# iospear320 register map
Registers from a debugger description file.
Registers are 32-bit, access not given, no defined reset value unless marked. A register's access mark holds for its fields unless they carry their own. Addresses are absolute; registers are grouped by the start of their names; lines under a group give offsets from that group; [hi:lo] are bit positions; {n}, {i} and the like mark numbered series; 'fields as' and 'values as' point back to an identical list; <NAME> marks a mode.

## PLL1
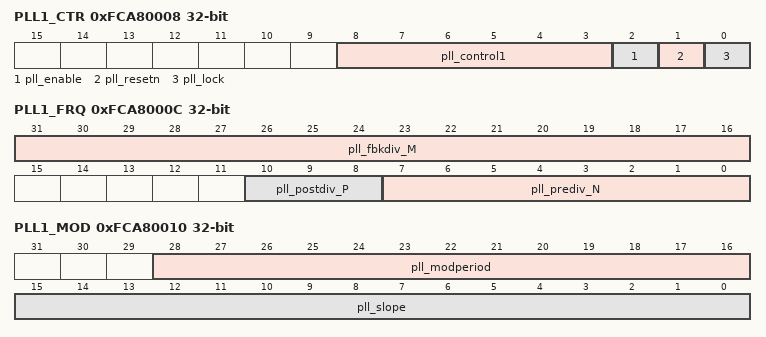
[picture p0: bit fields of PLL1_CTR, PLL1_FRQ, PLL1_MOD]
0xFCA80008 PLL1_CTR
  [8:3] pll_control1, [2] pll_enable, [1] pll_resetn, [0] pll_lock
0xFCA8000C PLL1_FRQ
  [31:16] pll_fbkdiv_M, [10:8] pll_postdiv_P, [7:0] pll_prediv_N
0xFCA80010 PLL1_MOD
  [28:16] pll_modperiod, [15:0] pll_slope

## PLL2
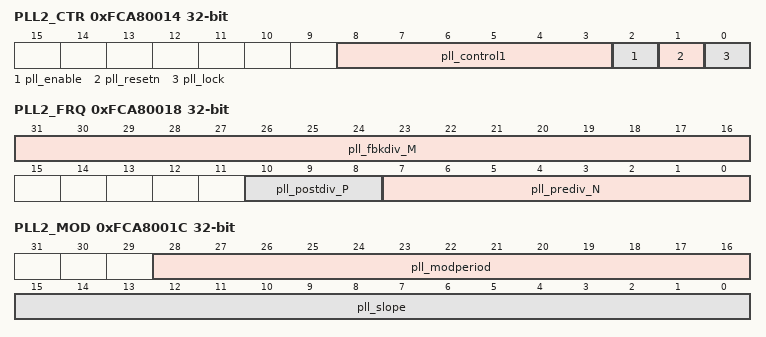
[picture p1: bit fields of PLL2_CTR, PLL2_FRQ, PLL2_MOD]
0xFCA80014 PLL2_CTR
  [8:3] pll_control1, [2] pll_enable, [1] pll_resetn, [0] pll_lock
0xFCA80018 PLL2_FRQ
  [31:16] pll_fbkdiv_M, [10:8] pll_postdiv_P, [7:0] pll_prediv_N
0xFCA8001C PLL2_MOD
  [28:16] pll_modperiod, [15:0] pll_slope

## PERIP1
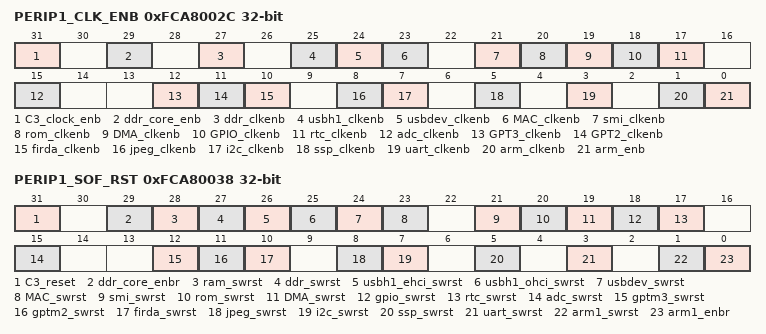
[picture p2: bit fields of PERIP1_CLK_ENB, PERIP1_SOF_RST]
0xFCA8002C PERIP1_CLK_ENB
  [31] C3_clock_enb, [29] ddr_core_enb, [27] ddr_clkenb, [25] usbh1_clkenb, [24] usbdev_clkenb, [23] MAC_clkenb, [21] smi_clkenb, [20] rom_clkenb, [19] DMA_clkenb, [18] GPIO_clkenb, [17] rtc_clkenb, [15] adc_clkenb, [12] GPT3_clkenb, [11] GPT2_clkenb, [10] firda_clkenb, [8] jpeg_clkenb, [7] i2c_clkenb, [5] ssp_clkenb, [3] uart_clkenb, [1] arm_clkenb, [0] arm_enb
0xFCA80038 PERIP1_SOF_RST
  [31] C3_reset, [29] ddr_core_enbr, [28] ram_swrst, [27] ddr_swrst, [26] usbh1_ehci_swrst, [25] usbh1_ohci_swrst, [24] usbdev_swrst, [23] MAC_swrst, [21] smi_swrst, [20] rom_swrst, [19] DMA_swrst, [18] gpio_swrst, [17] rtc_swrst, [15] adc_swrst, [12] gptm3_swrst, [11] gptm2_swrst, [10] firda_swrst, [8] jpeg_swrst, [7] i2c_swrst, [5] ssp_swrst, [3] uart_swrst, [1] arm1_swrst, [0] arm1_enbr

## RAS
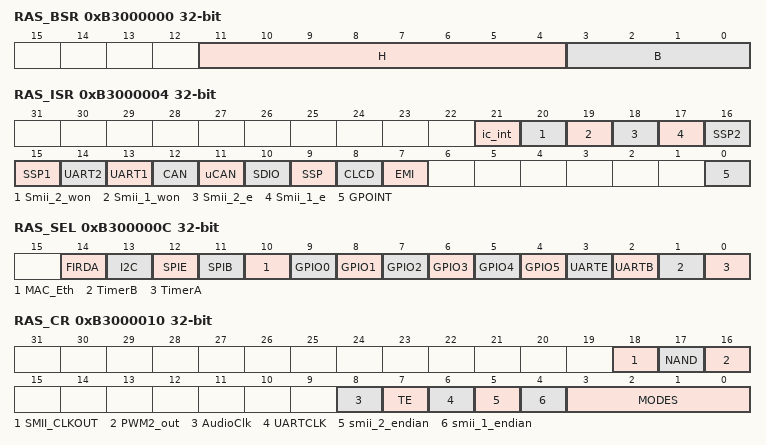
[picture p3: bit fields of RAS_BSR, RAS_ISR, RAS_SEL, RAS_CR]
0xB3000000 RAS_BSR
  [11:4] H, [3:0] B
0xB3000004 RAS_ISR
  [21] ic_int, [20] Smii_2_won, [19] Smii_1_won, [18] Smii_2_e, [17] Smii_1_e, [16] SSP2, [15] SSP1, [14] UART2, [13] UART1, [12] CAN, [11] uCAN, [10] SDIO, [9] SSP, [8] CLCD, [7] EMI, [0] GPOINT
0xB3000008 RAS_IMR
  [0] GPOINT
0xB300000C RAS_SEL
  [14] FIRDA, [13] I2C, [12] SPIE, [11] SPIB, [10] MAC_Eth, [9-n] GPIO{n} (n=0..5), [3] UARTE, [2] UARTB, [1] TimerB, [0] TimerA
0xB3000010 RAS_CR
  [18] SMII_CLKOUT, [17] NAND, [16] PWM2_out, [8] AudioClk, [7] TE, [6] UARTCLK, [5] smii_2_endian, [4] smii_1_endian, [3:0] MODES
0xB3000014 RAS_TD
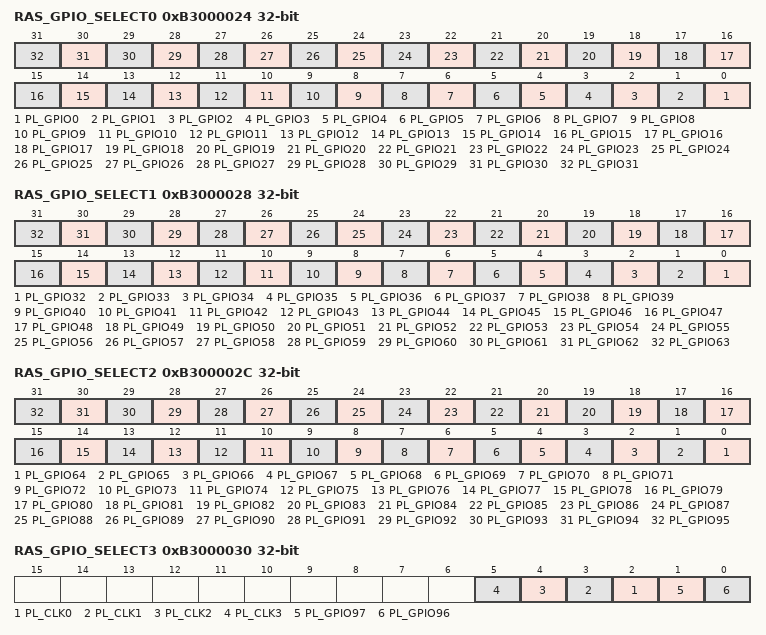
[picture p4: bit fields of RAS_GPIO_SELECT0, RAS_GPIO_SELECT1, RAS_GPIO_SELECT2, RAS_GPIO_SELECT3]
0xB3000024 RAS_GPIO_SELECT0
  [n] PL_GPIO{n} (n=0..31)
0xB3000028 RAS_GPIO_SELECT1
  [n-32] PL_GPIO{n} (n=32..63)
0xB300002C RAS_GPIO_SELECT2
  [n-64] PL_GPIO{n} (n=64..95)
0xB3000030 RAS_GPIO_SELECT3
  [n+2] PL_CLK{n} (n=0..3), [1] PL_GPIO97, [0] PL_GPIO96
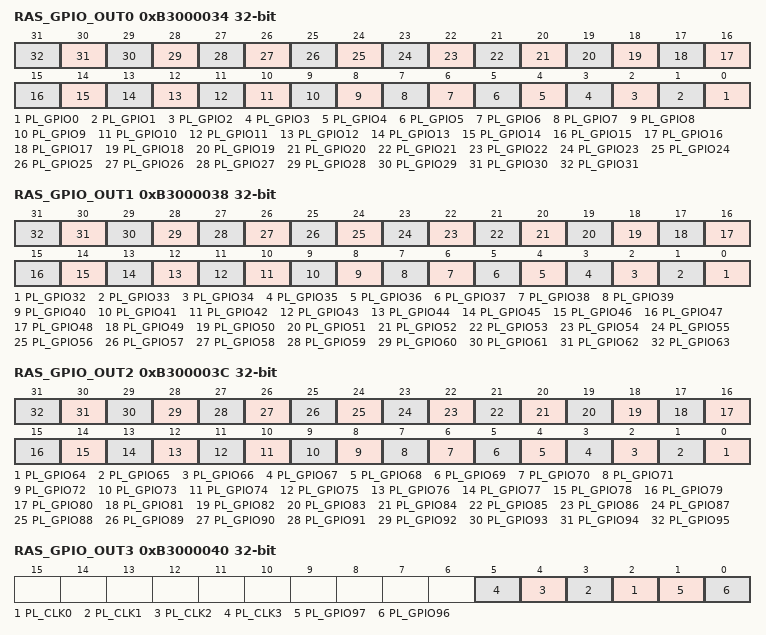
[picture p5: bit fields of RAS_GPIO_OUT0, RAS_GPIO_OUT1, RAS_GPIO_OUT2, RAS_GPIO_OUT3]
0xB3000034 RAS_GPIO_OUT0
  [n] PL_GPIO{n} (n=0..31)
0xB3000038 RAS_GPIO_OUT1
  [n-32] PL_GPIO{n} (n=32..63)
0xB300003C RAS_GPIO_OUT2
  [n-64] PL_GPIO{n} (n=64..95)
0xB3000040 RAS_GPIO_OUT3
  [n+2] PL_CLK{n} (n=0..3), [1] PL_GPIO97, [0] PL_GPIO96
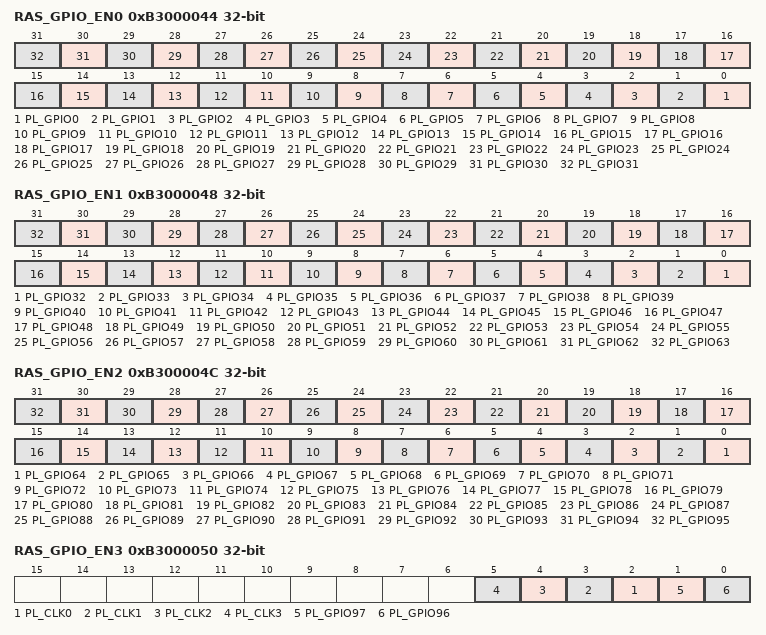
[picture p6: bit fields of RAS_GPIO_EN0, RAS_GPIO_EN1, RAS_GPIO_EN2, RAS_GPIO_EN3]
0xB3000044 RAS_GPIO_EN0
  [n] PL_GPIO{n} (n=0..31)
0xB3000048 RAS_GPIO_EN1
  [n-32] PL_GPIO{n} (n=32..63)
0xB300004C RAS_GPIO_EN2
  [n-64] PL_GPIO{n} (n=64..95)
0xB3000050 RAS_GPIO_EN3
  [n+2] PL_CLK{n} (n=0..3), [1] PL_GPIO97, [0] PL_GPIO96
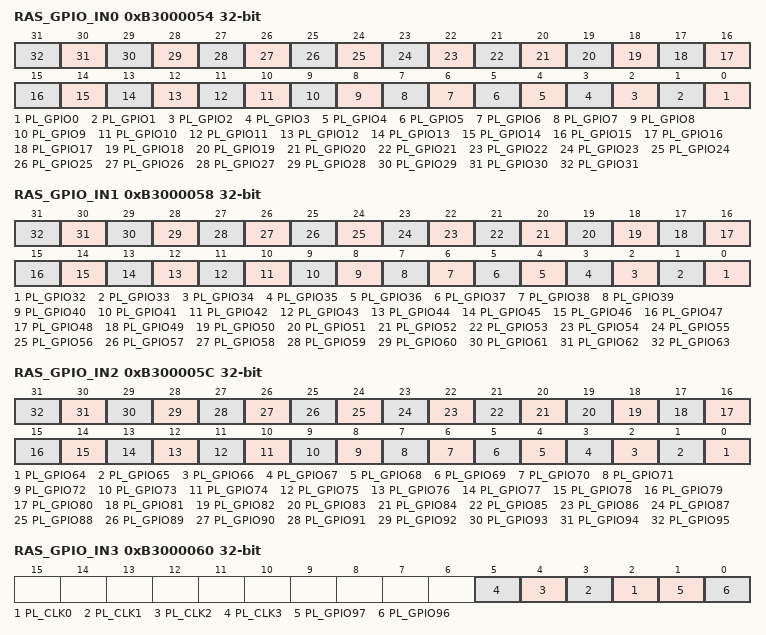
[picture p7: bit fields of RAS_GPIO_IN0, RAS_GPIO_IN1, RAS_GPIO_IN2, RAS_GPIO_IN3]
0xB3000054 RAS_GPIO_IN0
  [n] PL_GPIO{n} (n=0..31)
0xB3000058 RAS_GPIO_IN1
  [n-32] PL_GPIO{n} (n=32..63)
0xB300005C RAS_GPIO_IN2
  [n-64] PL_GPIO{n} (n=64..95)
0xB3000060 RAS_GPIO_IN3
  [n+2] PL_CLK{n} (n=0..3), [1] PL_GPIO97, [0] PL_GPIO96
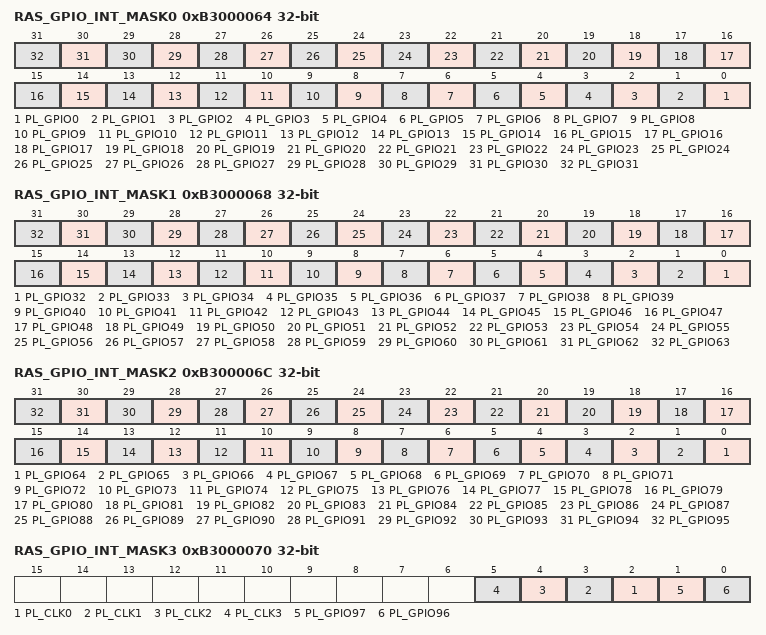
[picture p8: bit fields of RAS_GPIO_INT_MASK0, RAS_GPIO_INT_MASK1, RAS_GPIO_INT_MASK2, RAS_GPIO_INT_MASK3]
0xB3000064 RAS_GPIO_INT_MASK0
  [n] PL_GPIO{n} (n=0..31)
0xB3000068 RAS_GPIO_INT_MASK1
  [n-32] PL_GPIO{n} (n=32..63)
0xB300006C RAS_GPIO_INT_MASK2
  [n-64] PL_GPIO{n} (n=64..95)
0xB3000070 RAS_GPIO_INT_MASK3
  [n+2] PL_CLK{n} (n=0..3), [1] PL_GPIO97, [0] PL_GPIO96
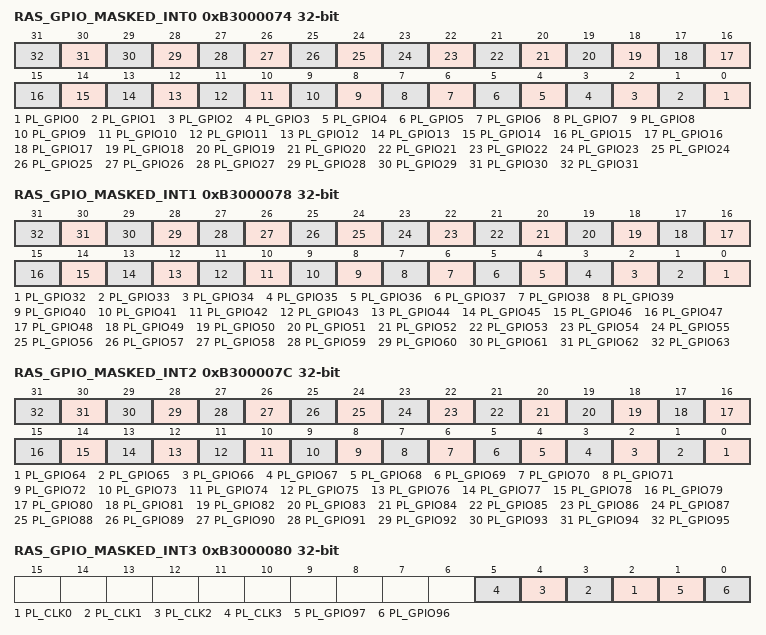
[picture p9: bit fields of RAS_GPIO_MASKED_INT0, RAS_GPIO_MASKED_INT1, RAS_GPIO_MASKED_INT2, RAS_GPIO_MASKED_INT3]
0xB3000074 RAS_GPIO_MASKED_INT0
  [n] PL_GPIO{n} (n=0..31)
0xB3000078 RAS_GPIO_MASKED_INT1
  [n-32] PL_GPIO{n} (n=32..63)
0xB300007C RAS_GPIO_MASKED_INT2
  [n-64] PL_GPIO{n} (n=64..95)
0xB3000080 RAS_GPIO_MASKED_INT3
  [n+2] PL_CLK{n} (n=0..3), [1] PL_GPIO97, [0] PL_GPIO96
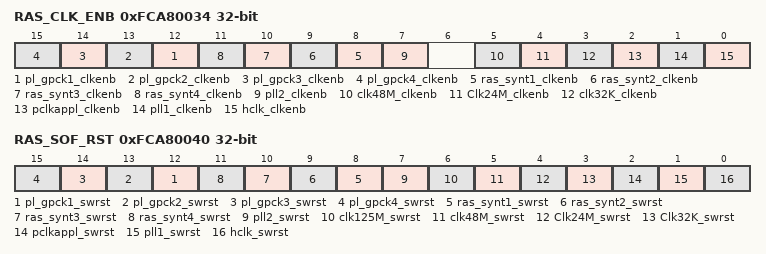
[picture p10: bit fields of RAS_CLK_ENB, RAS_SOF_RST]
0xFCA80034 RAS_CLK_ENB
  [n+11] pl_gpck{n}_clkenb (n=1..4), [n+7] ras_synt{n}_clkenb (n=1..4), [7] pll2_clkenb, [5] clk48M_clkenb, [4] Clk24M_clkenb, [3] clk32K_clkenb, [2] pclkappl_clkenb, [1] pll1_clkenb, [0] hclk_clkenb
0xFCA80040 RAS_SOF_RST
  [n+11] pl_gpck{n}_swrst (n=1..4), [n+7] ras_synt{n}_swrst (n=1..4), [7] pll2_swrst, [6] clk125M_swrst, [5] clk48M_swrst, [4] Clk24M_swrst, [3] Clk32K_swrst, [2] pclkappl_swrst, [1] pll1_swrst, [0] hclk_swrst
